# UPD70F3508 register map
Vendor: Renesas; Series: V850E2/Px4; File version: 1.0
CPU: other r0p0, little endian, no MPU, FPU, 4 interrupt priority bits
Registers are 8-bit, read-write, reset 0x0 unless marked. A register's access mark holds for its fields unless they carry their own. Offsets are from the block's base; [hi:lo] are bit positions; {n}, {i} and the like mark numbered series.

## ECC_RAM — On-chip RAM ECC Error Detection and Address Registers
Base 0xFF468000
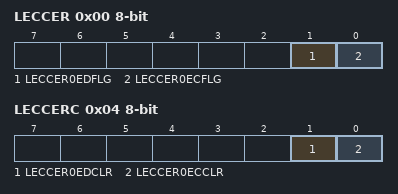
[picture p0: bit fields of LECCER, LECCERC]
0x00 LECCER ro — On-chip RAM ECC Error Flag Register
  [1] LECCER0EDFLG — On-chip RAM ECC uncorrectable error flag (0=no error, 1=uncorrectable error)
  [0] LECCER0ECFLG — On-chip RAM ECC correction flag (0=no correction, 1=correction occurred)
0x04 LECCERC — On-chip RAM ECC Error Flag Clear Register — writing 1 clears corresponding LECCER bits
  [1] LECCER0EDCLR — Clear LECCER.LECCER0EDFLG (0=no clear, 1=clear)
  [0] LECCER0ECCLR — Clear LECCER.LECCER0ECFLG (0=no clear, 1=clear)
0x08 LECADR 32-bit ro — On-chip RAM ECC Error Correction Address Register — holds address where ECC correction was applied
  [20:2] LECADR0A — On-chip RAM address where ECC correction was applied [20:2]
0x0C LEDADR 32-bit ro — On-chip RAM ECC Error Detection Address Register — holds address where ECC error was detected
  [20:2] LEDADR0A — On-chip RAM address where ECC error was encountered [20:2]

## FLASH_OPT — Flash Option-Byte and Product Identification Registers
Base 0xFF470000
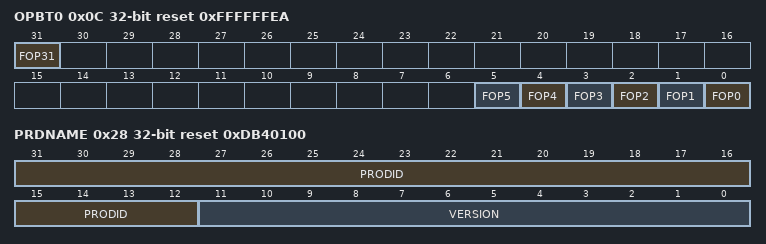
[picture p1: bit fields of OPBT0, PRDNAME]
0x0C OPBT0 32-bit ro reset 0xFFFFFFEA — Option Byte Verification Register
  [31] FOP31 — JTAG port switch: 0=enabled, 1=disabled
  [5] FOP5 — FlexRay clock (SCLK2) enable: 0=disabled, 1=enabled
  [4] FOP4 — Peripheral clock (PCLK) select bit 1 (see FOP[4:3] table)
  [3] FOP3 — Peripheral clock (PCLK) select bit 0 (see FOP[4:3] table)
  [2] FOP2 — CPU clock (HEAPCLK) select bit 2 (see FOP[2:0] table)
  [1] FOP1 — CPU clock (HEAPCLK) select bit 1 (see FOP[2:0] table)
  [0] FOP0 — CPU clock (HEAPCLK) select bit 0 (uPD70F3508/3509 only)
0x20 PRDSELL 32-bit ro reset 0x20FF — Product Selection Register Low (product identification)
0x24 PRDSELH 32-bit ro reset 0xFEDEC004 — Product Selection Register High (RAM start address and code flash size code)
0x28 PRDNAME 32-bit ro reset 0xDB40100 — Product Name Register (product identifier and version)
  [31:12] PRODID — Product identifier (bits 31:12); 0DB40H = uPD70F3508
  [11:0] VERSION — Product version information (bits 11:0)

## CSIH1_B0 — Queue-Equipped Three-Line Serial Interface H 1, Bank 0 (control/config registers at base0; CS0-CS3 only)
Base 0xFF6D0000
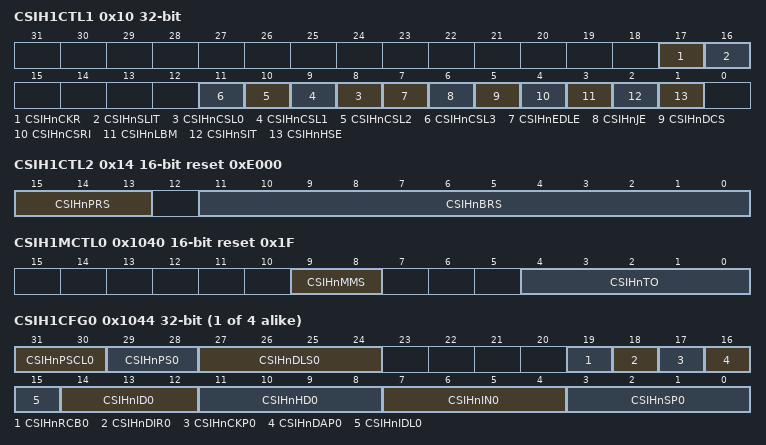
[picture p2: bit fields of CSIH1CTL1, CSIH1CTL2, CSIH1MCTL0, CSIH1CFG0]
0x10 CSIH1CTL1 32-bit — CSIH1 Control Register 1 — clock phase, interrupt timing, chip-select levels (CS0-CS3), job/loop-back/handshake modes
  [17] CSIHnCKR — Clock phase of CSIHnTSCK
  [16] CSIHnSLIT — Interrupt timing select for CSIHnTIC
  [n+8] CSIHnCSL{n} (n=0..3) — Chip-select {n} active output level
  [7] CSIHnEDLE — Extended data length mode enable
  [6] CSIHnJE — Job mode enable
  [5] CSIHnDCS — Data consistency check enable
  [4] CSIHnCSRI — Chip-select behavior after last transfer
  [3] CSIHnLBM — Loop-back mode enable
  [2] CSIHnSIT — Interrupt delay mode
  [1] CSIHnHSE — Handshake function enable
0x14 CSIH1CTL2 16-bit reset 0xE000 — CSIH1 Control Register 2 — operating mode, prescaler, baud rate
  [15:13] CSIHnPRS — Prescaler select [2:0]
  [11:0] CSIHnBRS — Baud rate select [11:0]
0x1040 CSIH1MCTL0 16-bit reset 0x1F — CSIH1 Memory Control Register 0 — memory mode and time-out setting
  [9:8] CSIHnMMS — Memory mode select [1:0]
  [4:0] CSIHnTO — Time-out setting [4:0]
{0x1044+4i} CSIH1CFG{i} 32-bit (i=0..3) — CSIH1 Configuration Register {i} — chip-select {i} protocol settings
  [31:30] CSIHnPSCL{i} — Prescaler select for CS{i} [1:0]
  [29:28] CSIHnPS{i} — Parity select for CS{i} [1:0]
  [27:24] CSIHnDLS{i} — Data length select for CS{i} [3:0]
  [19] CSIHnRCB{i} — Recessive config for CS{i}
  [18] CSIHnDIR{i} — Data direction for CS{i}
  [17] CSIHnCKP{i} — Clock phase for CS{i}
  [16] CSIHnDAP{i} — Data phase for CS{i}
  [15] CSIHnIDL{i} — Idle enforcement config for CS{i}
  [14:12] CSIHnID{i} — Idle time select for CS{i} [2:0]
  [11:8] CSIHnHD{i} — Hold time for CS{i} [3:0]
  [7:4] CSIHnIN{i} — Inter-data delay for CS{i} [3:0]
  [3:0] CSIHnSP{i} — Setup time for CS{i} [3:0]
